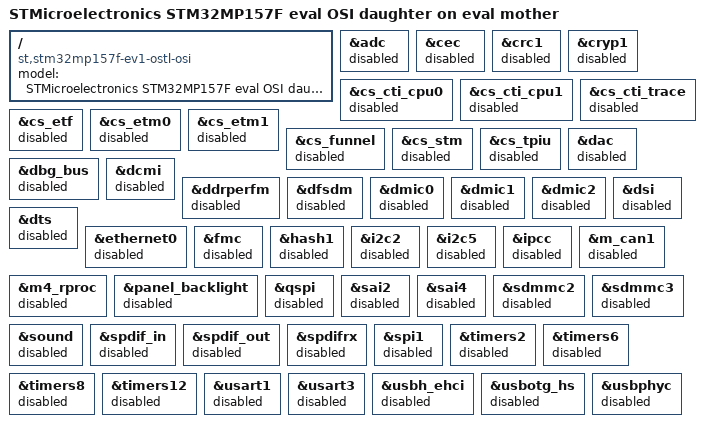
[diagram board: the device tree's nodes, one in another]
// SPDX-License-Identifier: (GPL-2.0-only OR BSD-3-Clause)
/*
 * Copyright (C) STMicroelectronics 2025 - All Rights Reserved
 * Author: Alexandre Torgue <alexandre.torgue@st.com> for STMicroelectronics.
 * Author: Pascal Paillet <p.paillet@st.com> for STMicroelectronics.
 */

/dts-v1/;

#include "stm32mp157f-ev1-ostl.dts"

/ {
	model = "STMicroelectronics STM32MP157F eval OSI daughter on eval mother";
	compatible = "st,stm32mp157f-ev1-ostl-osi", "st,stm32mp157f-ev1-ostl", "st,stm32mp157f-ev1", "st,stm32mp157f-ed1", "st,stm32mp157";
};

&adc {
	status = "disabled";
};

&cec {
	status = "disabled";
};

&crc1 {
	status = "disabled";
};

&cryp1 {
	status = "disabled";
};

&cs_cti_cpu0 {
	status = "disabled";
};

&cs_cti_cpu1 {
	status = "disabled";
};

&cs_cti_trace {
	status = "disabled";
};

&cs_etf {
	status = "disabled";
};

&cs_etm0 {
	status = "disabled";
};

&cs_etm1 {
	status = "disabled";
};

&cs_funnel {
	status = "disabled";
};

&cs_stm {
	status = "disabled";
};

&cs_tpiu {
	status = "disabled";
};

&dac {
	status = "disabled";
};

&dbg_bus {
	status = "disabled";
};

&dcmi {
	status = "disabled";
};

&ddrperfm {
	status = "disabled";
};

&dfsdm {
	status = "disabled";
};

&dmic0 {
	status = "disabled";
};

&dmic1 {
	status = "disabled";
};

&dmic2 {
	status = "disabled";
};

&dsi {
	status = "disabled";
};

&dts {
	status = "disabled";
};

&ethernet0 {
	status = "disabled";
};

&fmc {
	status = "disabled";
};

&hash1 {
	status = "disabled";
};

&i2c2 {
	status = "disabled";
};

&i2c5 {
	status = "disabled";
};

&ipcc {
	status = "disabled";
};

&m_can1 {
	status = "disabled";
};

&m4_rproc {
	status = "disabled";
};

&panel_backlight {
	status = "disabled";
};

&qspi {
	status = "disabled";
};

&sai2 {
	status = "disabled";
};

&sai4 {
	status = "disabled";
};

&sdmmc2 {
	status = "disabled";
};

&sdmmc3 {
	status = "disabled";
};

&sound {
	status = "disabled";
};

&spdif_in {
	status = "disabled";
};

&spdif_out {
	status = "disabled";
};

&spdifrx {
	status = "disabled";
};

&spi1 {
	status = "disabled";
};

&timers2 {
	status = "disabled";
};

&timers6 {
	status = "disabled";
};

&timers8 {
	status = "disabled";
};

&timers12 {
	status = "disabled";
};

&usart1 {
	status = "disabled";
};

&usart3 {
	status = "disabled";
};

&usbh_ehci {
	status = "disabled";
};

&usbotg_hs {
	status = "disabled";
};

&usbphyc {
	status = "disabled";
};
